# ESP32-S31 register map
Vendor: ESPRESSIF SYSTEMS (SHANGHAI) CO., LTD.; Series: ESP32 S-Series; File version: 1
CPU: RV32IMAFC r0p0, little endian, no MPU, FPU, 0 interrupt priority bits
Address unit: 32 bits
Registers are 32-bit, read-write, reset 0x0 unless marked. A register's access mark holds for its fields unless they carry their own. Offsets are from the block's base; [hi:lo] are bit positions; {n}, {i} and the like mark numbered series.

## MCPWM0 — Motor Control Pulse-Width Modulation 0
Base 0x20381000
Same registers: MCPWM1 0x20382000, MCPWM2 0x20383000, MCPWM3 0x20384000
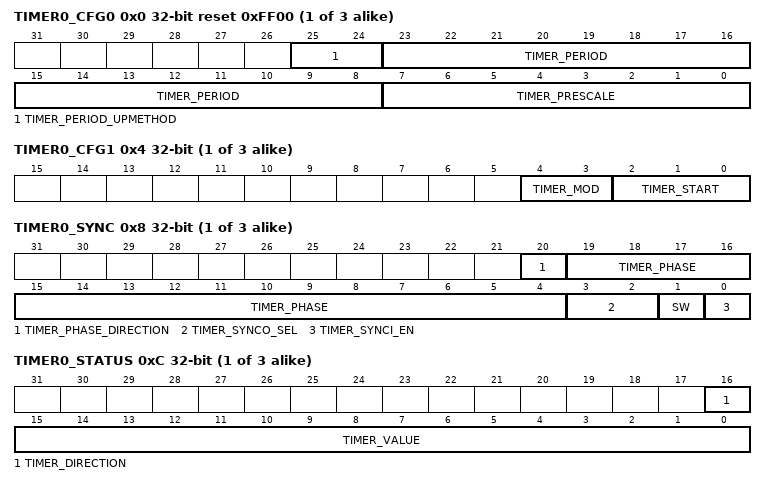
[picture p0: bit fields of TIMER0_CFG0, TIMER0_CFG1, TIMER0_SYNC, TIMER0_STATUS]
{0x0+0x10*i} TIMER{i}_CFG0 (i=0..2) reset 0xFF00 — PWM timer{i} period and update method configuration register.
  [25:24] TIMER_PERIOD_UPMETHOD — Configures the update method for active register of PWM timer%s period.\\0: Immediate\\1: TEZ\\2: Sync\\3: TEZ or sync\\TEZ here and below means timer equal zero event
  [23:8] TIMER_PERIOD — Configures the period shadow of PWM timer%s
  [7:0] TIMER_PRESCALE — Configures the prescaler value of timer%s, so that the period of PT0_clk = Period of PWM_clk * (PWM_TIMER%s_PRESCALE + 1)
{0x4+0x10*i} TIMER{i}_CFG1 (i=0..2) — PWM timer{i} working mode and start/stop control register.
  [4:3] TIMER_MOD — Configures the working mode of PWM timer%s.\\0: Freeze\\1: Increase mode\\2: Decrease mode\\3: Up-down mode
  [2:0] TIMER_START — Configures whether or not to start/stop PWM timer%s.\\0: If PWM timer%s starts, then stops at TEZ\\1: If timer%s starts, then stops at TEP\\2: PWM timer%s starts and runs on\\3: Timer%s starts and stops at the next TEZ\\4: Timer0 starts and stops at the next TEP.\\TEP here and below means the event that happens when the timer equals to period
{0x8+0x10*i} TIMER{i}_SYNC (i=0..2) — PWM timer{i} sync function configuration register.
  [20] TIMER_PHASE_DIRECTION — Configures the PWM timer%s's direction when timer%s mode is up-down mode.\\0: Increase\\1: Decrease
  [19:4] TIMER_PHASE — Configures the phase for timer%s reload on sync event.
  [3:2] TIMER_SYNCO_SEL — Configures the selection of PWM timer%s sync_out.\\0: Sync_in\\1: TEZ\\2: TEP\\3: Invalid, sync_out selects noting
  [1] SW — Configures the generation of software sync. Toggling this bit will trigger a software sync.
  [0] TIMER_SYNCI_EN — Configures whether or not to enable timer%s reloading with phase on sync input event is enabled.\\0: Disable\\1: Enable
{0xC+0x10*i} TIMER{i}_STATUS (i=0..2) ro — PWM timer{i} status register.
  [16] TIMER_DIRECTION — Represents current PWM timer%s counter direction.\\0: Increment\\1: Decrement
  [15:0] TIMER_VALUE — Represents current PWM timer%s counter value.
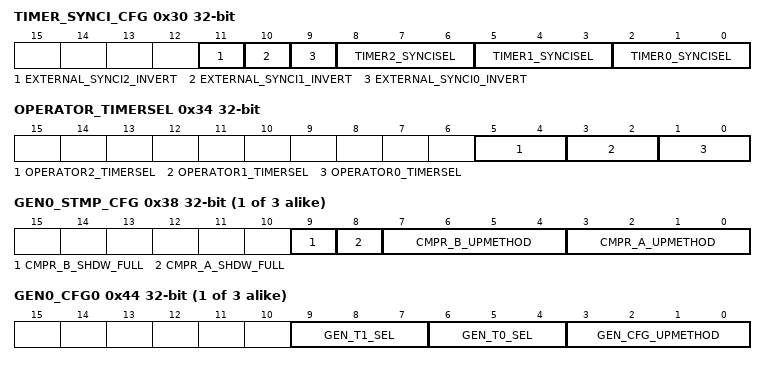
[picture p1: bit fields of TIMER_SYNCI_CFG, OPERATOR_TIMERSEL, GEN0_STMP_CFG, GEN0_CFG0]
0x30 TIMER_SYNCI_CFG — Synchronization input selection register for PWM timers.
  [11] EXTERNAL_SYNCI2_INVERT — Configures whether or not to invert SYNC2 from GPIO matrix.\\0: Not invert\\1: Invert
  [10] EXTERNAL_SYNCI1_INVERT — Configures whether or not to invert SYNC1 from GPIO matrix.\\0: Not invert\\1: Invert
  [9] EXTERNAL_SYNCI0_INVERT — Configures whether or not to invert SYNC0 from GPIO matrix.\\0: Not invert\\1: Invert
  [8:6] TIMER2_SYNCISEL — Configures the selection of sync input for PWM timer2.\\1: PWM timer0 sync_out\\2: PWM timer1 sync_out\\3: PWM timer2 sync_out\\4: SYNC0 from GPIO matrix\\5: SYNC1 from GPIO matrix\\6: SYNC2 from GPIO matrix\\Other values: No sync input selected
  [5:3] TIMER1_SYNCISEL — Configures the selection of sync input for PWM timer1.\\1: PWM timer0 sync_out\\2: PWM timer1 sync_out\\3: PWM timer2 sync_out\\4: SYNC0 from GPIO matrix\\5: SYNC1 from GPIO matrix\\6: SYNC2 from GPIO matrix\\Other values: No sync input selected
  [2:0] TIMER0_SYNCISEL — Configures the selection of sync input for PWM timer0.\\1: PWM timer0 sync_out\\2: PWM timer1 sync_out\\3: PWM timer2 sync_out\\4: SYNC0 from GPIO matrix\\5: SYNC1 from GPIO matrix\\6: SYNC2 from GPIO matrix\\Other values: No sync input selected
0x34 OPERATOR_TIMERSEL — PWM operator's timer select register
  [5:4] OPERATOR2_TIMERSEL — Configures which PWM timer will be the timing reference for PWM operator2.\\0: Timer0\\1: Timer1\\2: Timer2\\3: Invalid, will select timer2
  [3:2] OPERATOR1_TIMERSEL — Configures which PWM timer will be the timing reference for PWM operator1.\\0: Timer0\\1: Timer1\\2: Timer2\\3: Invalid, will select timer2
  [1:0] OPERATOR0_TIMERSEL — Configures which PWM timer will be the timing reference for PWM operator0.\\0: Timer0\\1: Timer1\\2: Timer2\\3: Invalid, will select timer2
{0x38+0x38*i} GEN{i}_STMP_CFG (i=0..2) — Generator{i} time stamp registers A and B transfer status and update method register
  [9] CMPR_B_SHDW_FULL — Represents whether or not generator%s time stamp B's shadow reg is transferred.\\0: B's active reg has been updated with shadow register latest value.\\1: B's shadow reg is filled and waiting to be transferred to B's active reg
  [8] CMPR_A_SHDW_FULL — Represents whether or not generator%s time stamp A's shadow reg is transferred.\\0: A's active reg has been updated with shadow register latest value.\\1: A's shadow reg is filled and waiting to be transferred to A's active reg
  [7:4] CMPR_B_UPMETHOD — Configures the update method for PWM generator %s time stamp B's active register.\\0: Immediately\\Bit0 is set to 1: TEZ\\Bit1 is set to 1: TEP\\Bit2 is set to 1: Sync\\Bit3 is set to 1: Disable the update
  [3:0] CMPR_A_UPMETHOD — Configures the update method for PWM generator %s time stamp A's active register.\\0: Immediately\\Bit0 is set to 1: TEZ\\Bit1 is set to 1: TEP\\Bit2 is set to 1: Sync\\Bit3 is set to 1: Disable the update
{0x3C+0x38*i} GEN{i}_TSTMP_A (i=0..2) — Generator{i} time stamp A's shadow register
  [15:0] CMPR_A — Configures the value of PWM generator %s time stamp A's shadow register.
{0x40+0x38*i} GEN{i}_TSTMP_B (i=0..2) — Generator{i} time stamp B's shadow register
  [15:0] CMPR_B — Configures the value of PWM generator %s time stamp B's shadow register.
{0x44+0x38*i} GEN{i}_CFG0 (i=0..2) — Generator{i} fault event T0 and T1 configuration register
  [9:7] GEN_T1_SEL — Configures source selection for PWM generator %s event_t1, take effect immediately.\\0: fault_event0\\1: fault_event1\\2: fault_event2\\3: sync_taken\\4: Invalid, Select nothing
  [6:4] GEN_T0_SEL — Configures source selection for PWM generator %s event_t0, take effect immediately.\\0: fault_event0\\1: fault_event1\\2: fault_event2\\3: sync_taken\\4: Invalid, Select nothing
  [3:0] GEN_CFG_UPMETHOD — Configures update method for PWM generator %s's active register.\\0: Immediately\\Bit0 is set to 1: TEZ\\Bit1 is set to 1: TEP\\Bit2 is set to 1: Sync\\Bit3 is set to 1: Disable the update
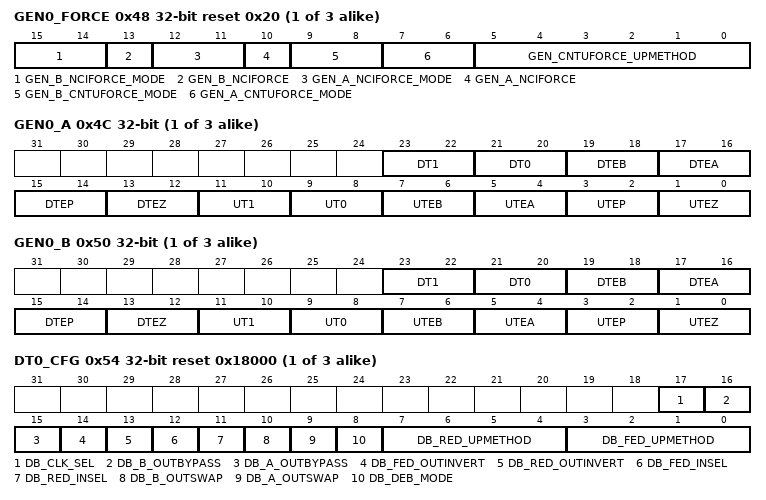
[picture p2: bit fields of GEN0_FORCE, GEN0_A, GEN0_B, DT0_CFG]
{0x48+0x38*i} GEN{i}_FORCE (i=0..2) reset 0x20 — Generator{i} output signal force mode register.
  [15:14] GEN_B_NCIFORCE_MODE — Configures non-continuous immediate software force mode for PWM%s B.\\0: Disabled\\1: Low\\2: High\\3: Disabled
  [13] GEN_B_NCIFORCE — Configures the generation of non-continuous immediate software-force event for PWM%s B, a toggle will trigger a force event.
  [12:11] GEN_A_NCIFORCE_MODE — Configures non-continuous immediate software force mode for PWM%s A.\\0: Disabled\\1: Low\\2: High\\3: Disabled
  [10] GEN_A_NCIFORCE — Configures the generation of non-continuous immediate software-force event for PWM%s A, a toggle will trigger a force event.
  [9:8] GEN_B_CNTUFORCE_MODE — Configures continuous software force mode for PWM%s B.\\0: Disabled\\1: Low\\2: High\\3: Disabled
  [7:6] GEN_A_CNTUFORCE_MODE — Configures continuous software force mode for PWM%s A.\\0: Disabled\\1: Low\\2: High\\3: Disabled
  [5:0] GEN_CNTUFORCE_UPMETHOD — Configures update method for continuous software force of PWM generator%s.\\0: Immediately\\Bit0 is set to 1: TEZ\\Bit1 is set to 1: TEP\\Bit2 is set to 1: TEA\\Bit3 is set to 1: TEB\\Bit4 is set to 1: Sync\\Bit5 is set to 1: Disable update. TEA/B here and below means an event generated when the timer's value equals to that of register A/B.
{0x4C+0x38*i} GEN{i}_A (i=0..2) — PWM{i} output signal A actions configuration register
  [23:22] DT1 — Configures action on PWM%s A triggered by event_t1 when timer decreasing.\\0: No change\\1: Low\\2: High\\3: Toggle
  [21:20] DT0 — Configures action on PWM%s A triggered by event_t0 when timer decreasing.\\0: No change\\1: Low\\2: High\\3: Toggle
  [19:18] DTEB — Configures action on PWM%s A triggered by event TEB when timer decreasing.\\0: No change\\1: Low\\2: High\\3: Toggle
  [17:16] DTEA — Configures action on PWM%s A triggered by event TEA when timer decreasing.\\0: No change\\1: Low\\2: High\\3: Toggle
  [15:14] DTEP — Configures action on PWM%s A triggered by event TEP when timer decreasing.\\0: No change\\1: Low\\2: High\\3: Toggle
  [13:12] DTEZ — Configures action on PWM%s A triggered by event TEZ when timer decreasing.\\0: No change\\1: Low\\2: High\\3: Toggle
  [11:10] UT1 — Configures action on PWM%s A triggered by event_t1 when timer increasing.\\0: No change\\1: Low\\2: High\\3: Toggle
  [9:8] UT0 — Configures action on PWM%s A triggered by event_t0 when timer increasing.\\0: No change\\1: Low\\2: High\\3: Toggle
  [7:6] UTEB — Configures action on PWM%s A triggered by event TEB when timer increasing.\\0: No change\\1: Low\\2: High\\3: Toggle
  [5:4] UTEA — Configures action on PWM%s A triggered by event TEA when timer increasing.\\0: No change\\1: Low\\2: High\\3: Toggle
  [3:2] UTEP — Configures action on PWM%s A triggered by event TEP when timer increasing.\\0: No change\\1: Low\\2: High\\3: Toggle
  [1:0] UTEZ — Configures action on PWM%s A triggered by event TEZ when timer increasing.\\0: No change\\1: Low\\2: High\\3: Toggle
{0x50+0x38*i} GEN{i}_B (i=0..2) — PWM{i} output signal B actions configuration register
  [23:22] DT1 — Configures action on PWM%s B triggered by event_t1 when timer decreasing.\\0: No change\\1: Low\\2: High\\3: Toggle
  [21:20] DT0 — Configures action on PWM%s B triggered by event_t0 when timer decreasing.\\0: No change\\1: Low\\2: High\\3: Toggle
  [19:18] DTEB — Configures action on PWM%s B triggered by event TEB when timer decreasing.\\0: No change\\1: Low\\2: High\\3: Toggle
  [17:16] DTEA — Configures action on PWM%s B triggered by event TEA when timer decreasing.\\0: No change\\1: Low\\2: High\\3: Toggle
  [15:14] DTEP — Configures action on PWM%s B triggered by event TEP when timer decreasing.\\0: No change\\1: Low\\2: High\\3: Toggle
  [13:12] DTEZ — Configures action on PWM%s B triggered by event TEZ when timer decreasing.\\0: No change\\1: Low\\2: High\\3: Toggle
  [11:10] UT1 — Configures action on PWM%s B triggered by event_t1 when timer increasing.\\0: No change\\1: Low\\2: High\\3: Toggle
  [9:8] UT0 — Configures action on PWM%s B triggered by event_t0 when timer increasing.\\0: No change\\1: Low\\2: High\\3: Toggle
  [7:6] UTEB — Configures action on PWM%s B triggered by event TEB when timer increasing.\\0: No change\\1: Low\\2: High\\3: Toggle
  [5:4] UTEA — Configures action on PWM%s B triggered by event TEA when timer increasing.\\0: No change\\1: Low\\2: High\\3: Toggle
  [3:2] UTEP — Configures action on PWM%s B triggered by event TEP when timer increasing.\\0: No change\\1: Low\\2: High\\3: Toggle
  [1:0] UTEZ — Configures action on PWM%s B triggered by event TEZ when timer increasing.\\0: No change\\1: Low\\2: High\\3: Toggle
{0x54+0x38*i} DT{i}_CFG (i=0..2) reset 0x18000 — Dead time configuration register
  [17] DB_CLK_SEL — Configures dead time generator %s clock selection.\\0: PWM_clk\\1: PT_clk
  [16] DB_B_OUTBYPASS — Configures S0 in table.
  [15] DB_A_OUTBYPASS — Configures S1 in table.
  [14] DB_FED_OUTINVERT — Configures S3 in table.
  [13] DB_RED_OUTINVERT — Configures S2 in table.
  [12] DB_FED_INSEL — Configures S5 in table.
  [11] DB_RED_INSEL — Configures S4 in table.
  [10] DB_B_OUTSWAP — Configures S7 in table.
  [9] DB_A_OUTSWAP — Configures S6 in table.
  [8] DB_DEB_MODE — Configures S8 in table, dual-edge B mode.\\0: fed/red take effect on different path separately\\1: fed/red take effect on B path, A out is in bypass or dulpB mode
  [7:4] DB_RED_UPMETHOD — Configures update method for RED (rising edge delay) active register.\\0: Immediate\\Bit0 is set to 1: TEZ\\Bit1 is set to 1: TEP\\Bit2 is set to 1: Sync\\Bit3 is set to 1: Disable the update
  [3:0] DB_FED_UPMETHOD — Configures update method for FED (Falling edge delay) active register.\\0: Immediate\\Bit0 is set to 1: TEZ\\Bit1 is set to 1: TEP\\Bit2 is set to 1: Sync\\Bit3 is set to 1: Disable the update
{0x58+0x38*i} DT{i}_FED_CFG (i=0..2) — Falling edge delay (FED) shadow register
  [15:0] DB_FED — Configures shadow register for FED.
{0x5C+0x38*i} DT{i}_RED_CFG (i=0..2) — Rising edge delay (RED) shadow register
  [15:0] DB_RED — Configures shadow register for RED.
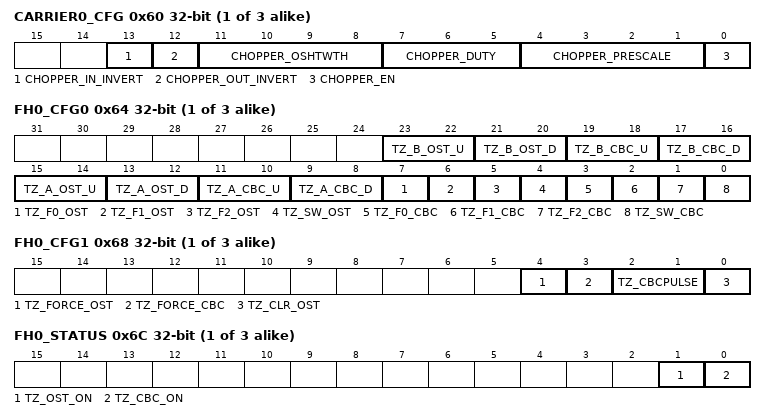
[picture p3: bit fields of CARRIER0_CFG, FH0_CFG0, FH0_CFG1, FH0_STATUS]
{0x60+0x38*i} CARRIER{i}_CFG (i=0..2) — Carrier{i} configuration register
  [13] CHOPPER_IN_INVERT — Configures whether or not to invert the input of PWM%s A and PWM%s B for this submodule.\\0: Normal\\1: Invert
  [12] CHOPPER_OUT_INVERT — Configures whether or not to invert the output of PWM%s A and PWM%s B for this submodule.\\0: Normal\\1: Invert
  [11:8] CHOPPER_OSHTWTH — Configures width of the first pulse. Measurement unit: Periods of the carrier.
  [7:5] CHOPPER_DUTY — Configures carrier duty. Duty = PWM_CARRIER%s_DUTY / 8
  [4:1] CHOPPER_PRESCALE — Configures the prescale value of PWM carrier%s clock (PC_clk), so that period of PC_clk = period of PWM_clk * (PWM_CARRIER%s_PRESCALE + 1)
  [0] CHOPPER_EN — Configures whether or not to enable carrier%s.\\0: Bypassed\\1: Enabled
{0x64+0x38*i} FH{i}_CFG0 (i=0..2) — PWM{i} A and PWM{i} B trip events actions configuration register
  [23:22] TZ_B_OST_U — Configures one-shot mode action on PWM%s B when fault event occurs and timer is increasing.\\0: Do nothing\\1: Force low\\2: Force high\\3: Toggle
  [21:20] TZ_B_OST_D — Configures one-shot mode action on PWM%s B when fault event occurs and timer is decreasing.\\0: Do nothing\\1: Force low\\2: Force high\\3: Toggle
  [19:18] TZ_B_CBC_U — Configures cycle-by-cycle mode action on PWM%s B when fault event occurs and timer is increasing.\\0: Do nothing\\1: Force low\\2: Force high\\3: Toggle
  [17:16] TZ_B_CBC_D — Configures cycle-by-cycle mode action on PWM%s B when fault event occurs and timer is decreasing.\\0: Do nothing\\1: Force low\\2: Force high\\3: Toggle
  [15:14] TZ_A_OST_U — Configures one-shot mode action on PWM%s A when fault event occurs and timer is increasing.\\0: Do nothing\\1: Force low\\2: Force high\\3: Toggle
  [13:12] TZ_A_OST_D — Configures one-shot mode action on PWM%s A when fault event occurs and timer is decreasing.\\0: Do nothing\\1: Force low\\2: Force high\\3: Toggle
  [11:10] TZ_A_CBC_U — Configures cycle-by-cycle mode action on PWM%s A when fault event occurs and timer is increasing.\\0: Do nothing\\1: Force low\\2: Force high\\3: Toggle
  [9:8] TZ_A_CBC_D — Configures cycle-by-cycle mode action on PWM%s A when fault event occurs and timer is decreasing.\\0: Do nothing\\1: Force low\\2: Force high\\3: Toggle
  [7] TZ_F0_OST — Configures whether or not event_f0 will trigger one-shot mode action.\\0: Disable\\1: Enable
  [6] TZ_F1_OST — Configures whether or not event_f1 will trigger one-shot mode action.\\0: Disable\\1: Enable
  [5] TZ_F2_OST — Configures whether or not event_f2 will trigger one-shot mode action.\\0: Disable\\1: Enable
  [4] TZ_SW_OST — Configures whether or not to enable software force one-shot mode action.\\0: Disable\\1: Enable
  [3] TZ_F0_CBC — Configures whether or not event_f0 will trigger cycle-by-cycle mode action.\\0: Disable\\1: Enable
  [2] TZ_F1_CBC — Configures whether or not event_f1 will trigger cycle-by-cycle mode action.\\0: Disable\\1: Enable
  [1] TZ_F2_CBC — Configures whether or not event_f2 will trigger cycle-by-cycle mode action.\\0: Disable\\1: Enable
  [0] TZ_SW_CBC — Configures whether or not to enable software force cycle-by-cycle mode action.\\0: Disable\\1: Enable
{0x68+0x38*i} FH{i}_CFG1 (i=0..2) — Software triggers for fault handler actions configuration register
  [4] TZ_FORCE_OST — Configures the generation of software one-shot mode action. A toggle (software negate its value) triggers a one-shot mode action.
  [3] TZ_FORCE_CBC — Configures the generation of software cycle-by-cycle mode action. A toggle (software negate its value) triggers a cycle-by-cycle mode action.
  [2:1] TZ_CBCPULSE — Configures the refresh moment selection of cycle-by-cycle mode action.\\0: Select nothing, will not refresh\\Bit0 is set to 1: TEZ\\Bit1 is set to 1: TEP
  [0] TZ_CLR_OST — Configures the generation of software one-shot mode action clear. A toggle (software negate its value) triggers a clear for on going one-shot mode action.
{0x6C+0x38*i} FH{i}_STATUS (i=0..2) ro — Fault events status register
  [1] TZ_OST_ON — Represents whether or not an one-shot mode action is on going.\\0:No action\\1: On going
  [0] TZ_CBC_ON — Represents whether or not an cycle-by-cycle mode action is on going.\\0:No action\\1: On going
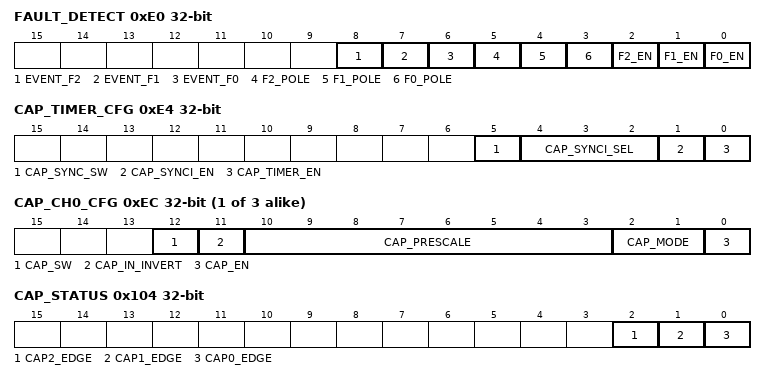
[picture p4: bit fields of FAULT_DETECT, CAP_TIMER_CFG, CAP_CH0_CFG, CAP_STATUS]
0xE0 FAULT_DETECT access per field — Fault detection configuration and status register
  [8] EVENT_F2 ro — Represents whether or not an event_f2 is on going.\\0: No action\\1: On going
  [7] EVENT_F1 ro — Represents whether or not an event_f1 is on going.\\0: No action\\1: On going
  [6] EVENT_F0 ro — Represents whether or not an event_f0 is on going.\\0: No action\\1: On going
  [5] F2_POLE rw — Configures event_f2 trigger polarity on FAULT2 source from GPIO matrix.\\0: Level low\\1: Level high
  [4] F1_POLE rw — Configures event_f1 trigger polarity on FAULT1 source from GPIO matrix.\\0: Level low\\1: Level high
  [3] F0_POLE rw — Configures event_f0 trigger polarity on FAULT0 source from GPIO matrix.\\0: Level low\\1: Level high
  [2] F2_EN rw — Configures whether or not to enable event_f2 generation.\\0: Disable\\1: Enable
  [1] F1_EN rw — Configures whether or not to enable event_f1 generation.\\0: Disable\\1: Enable
  [0] F0_EN rw — Configures whether or not to enable event_f0 generation.\\0: Disable\\1: Enable
0xE4 CAP_TIMER_CFG access per field — Capture timer configuration register
  [5] CAP_SYNC_SW wo — Configures the generation of a capture timer sync when reg_cap_synci_en is 1.\\0: Invalid, No effect\\1: Trigger a capture timer sync, capture timer is loaded with value in phase register
  [4:2] CAP_SYNCI_SEL rw — Configures the selection of capture module sync input.\\0: None\\1: Timer0 sync_out\\2: Timer1 sync_out\\3: Timer2 sync_out\\4: SYNC0 from GPIO matrix\\5: SYNC1 from GPIO matrix\\6: SYNC2 from GPIO matrix\\7: None
  [1] CAP_SYNCI_EN rw — Configures whether or not to enable capture timer sync.\\0: Disable\\1: Enable
  [0] CAP_TIMER_EN rw — Configures whether or not to enable capture timer increment.\\0: Disable\\1: Enable
0xE8 CAP_TIMER_PHASE — Capture timer sync phase register
  [31:0] CAP_PHASE — Configures phase value for capture timer sync operation.
{0xEC+4i} CAP_CH{i}_CFG (i=0..2) access per field — Capture channel {i} configuration register
  [12] CAP_SW wo — Configures the generation of software capture.\\0: Invalid, No effect\\1: Trigger a software forced capture on channel %s
  [11] CAP_IN_INVERT rw — Configures whether or not to invert CAP%s from GPIO matrix before prescale.\\0: Normal\\1: Invert
  [10:3] CAP_PRESCALE rw — Configures prescale value on possitive edge of CAP%s. Prescale value = PWM_CAP%s_PRESCALE + 1
  [2:1] CAP_MODE rw — Configures which edge of capture on channel %s after prescaling is used.\\0: None\\Bit0 is set to 1: Rnable capture on the negative edge\\Bit1 is set to 1: Enable capture on the positive edge
  [0] CAP_EN rw — Configures whether or not to enable capture on channel %s.\\0: Disable\\1: Enable
{0xF8+4i} CAP_CH{i} (i=0..2) ro — CAP{i} capture value register
  [31:0] CAP_VALUE — Represents value of last capture on CAP%s
0x104 CAP_STATUS ro — Last capture trigger edge information register
  [2] CAP2_EDGE — Represents edge of last capture trigger on channel2.\\0: Posedge\\1: Negedge
  [1] CAP1_EDGE — Represents edge of last capture trigger on channel1.\\0: Posedge\\1: Negedge
  [0] CAP0_EDGE — Represents edge of last capture trigger on channel0.\\0: Posedge\\1: Negedge
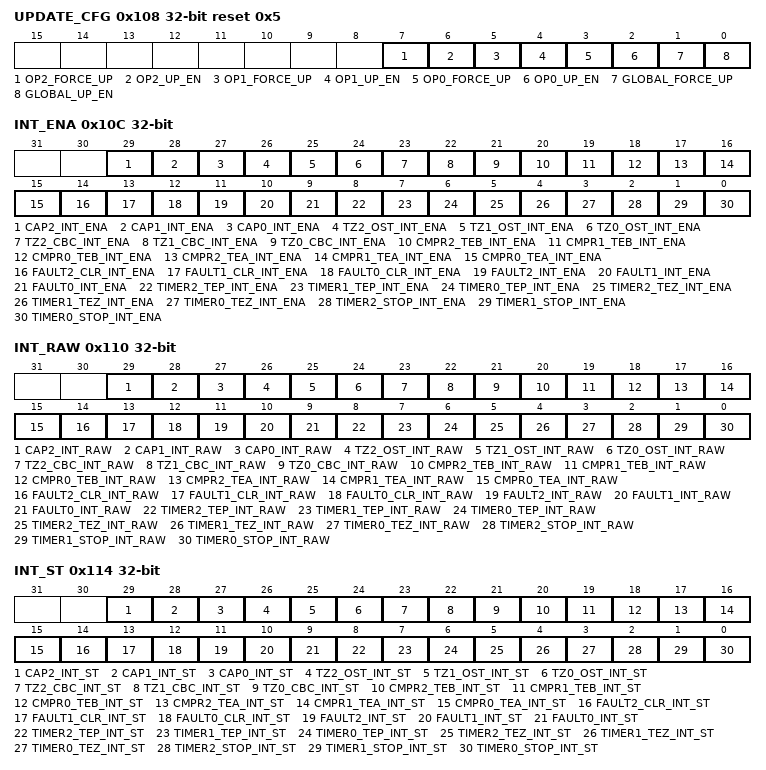
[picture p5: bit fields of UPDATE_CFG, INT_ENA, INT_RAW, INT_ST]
0x108 UPDATE_CFG reset 0x5 — Generator Update configuration register
  [7] OP2_FORCE_UP — Configures the generation of forced update for active registers in PWM operator2. A toggle (software invert its value) will trigger a forced update. Valid only when MCPWM_GLOBAL_UP_EN and MCPWM_OP2_UP_EN are both set to 1.
  [6] OP2_UP_EN — Configures whether or not to enable update of active registers in PWM operator2. Valid only when PWM_GLOBAL_UP_EN is set to 1.\\0: Disable\\1: Enable
  [5] OP1_FORCE_UP — Configures the generation of forced update for active registers in PWM operator1. A toggle (software invert its value) will trigger a forced update. Valid only when MCPWM_GLOBAL_UP_EN and MCPWM_OP1_UP_EN are both set to 1.
  [4] OP1_UP_EN — Configures whether or not to enable update of active registers in PWM operator1. Valid only when PWM_GLOBAL_UP_EN is set to 1.\\0: Disable\\1: Enable
  [3] OP0_FORCE_UP — Configures the generation of forced update for active registers in PWM operator0. A toggle (software invert its value) will trigger a forced update. Valid only when MCPWM_GLOBAL_UP_EN and MCPWM_OP0_UP_EN are both set to 1.
  [2] OP0_UP_EN — Configures whether or not to enable update of active registers in PWM operator0. Valid only when PWM_GLOBAL_UP_EN is set to 1.\\0: Disable\\1: Enable
  [1] GLOBAL_FORCE_UP — Configures the generation of global forced update for all active registers in MCPWM module. A toggle (software invert its value) will trigger a global forced update. Valid only when MCPWM_GLOBAL_UP_EN and MCPWM_OP0/1/2_UP_EN are both set to 1.
  [0] GLOBAL_UP_EN — Configures whether or not to enable global update for all active registers in MCPWM module.\\0: Disable\\1: Enable
0x10C INT_ENA — Interrupt enable register
  [29] CAP2_INT_ENA — Enable bit: Write 1 to enable the interrupt triggered by capture on CAP2.
  [28] CAP1_INT_ENA — Enable bit: Write 1 to enable the interrupt triggered by capture on CAP1.
  [27] CAP0_INT_ENA — Enable bit: Write 1 to enable the interrupt triggered by capture on CAP0.
  [26] TZ2_OST_INT_ENA — Enable bit: Write 1 to enable the interrupt triggered by a one-shot mode action on PWM2.
  [25] TZ1_OST_INT_ENA — Enable bit: Write 1 to enable the interrupt triggered by a one-shot mode action on PWM1.
  [24] TZ0_OST_INT_ENA — Enable bit: Write 1 to enable the interrupt triggered by a one-shot mode action on PWM0.
  [23] TZ2_CBC_INT_ENA — Enable bit: Write 1 to enable the interrupt triggered by a cycle-by-cycle mode action on PWM2.
  [22] TZ1_CBC_INT_ENA — Enable bit: Write 1 to enable the interrupt triggered by a cycle-by-cycle mode action on PWM1.
  [21] TZ0_CBC_INT_ENA — Enable bit: Write 1 to enable the interrupt triggered by a cycle-by-cycle mode action on PWM0.
  [20] CMPR2_TEB_INT_ENA — Enable bit: Write 1 to enable the interrupt triggered by a PWM operator 2 TEB event.
  [19] CMPR1_TEB_INT_ENA — Enable bit: Write 1 to enable the interrupt triggered by a PWM operator 1 TEB event.
  [18] CMPR0_TEB_INT_ENA — Enable bit: Write 1 to enable the interrupt triggered by a PWM operator 0 TEB event.
  [17] CMPR2_TEA_INT_ENA — Enable bit: Write 1 to enable the interrupt triggered by a PWM operator 2 TEA event.
  [16] CMPR1_TEA_INT_ENA — Enable bit: Write 1 to enable the interrupt triggered by a PWM operator 1 TEA event.
  [15] CMPR0_TEA_INT_ENA — Enable bit: Write 1 to enable the interrupt triggered by a PWM operator 0 TEA event.
  [14] FAULT2_CLR_INT_ENA — Enable bit: Write 1 to enable the interrupt triggered when event_f2 clears.
  [13] FAULT1_CLR_INT_ENA — Enable bit: Write 1 to enable the interrupt triggered when event_f1 clears.
  [12] FAULT0_CLR_INT_ENA — Enable bit: Write 1 to enable the interrupt triggered when event_f0 clears.
  [11] FAULT2_INT_ENA — Enable bit: Write 1 to enable the interrupt triggered when event_f2 starts.
  [10] FAULT1_INT_ENA — Enable bit: Write 1 to enable the interrupt triggered when event_f1 starts.
  [9] FAULT0_INT_ENA — Enable bit: Write 1 to enable the interrupt triggered when event_f0 starts.
  [8] TIMER2_TEP_INT_ENA — Enable bit: Write 1 to enable the interrupt triggered by a PWM timer 2 TEP event.
  [7] TIMER1_TEP_INT_ENA — Enable bit: Write 1 to enable the interrupt triggered by a PWM timer 1 TEP event.
  [6] TIMER0_TEP_INT_ENA — Enable bit: Write 1 to enable the interrupt triggered by a PWM timer 0 TEP event.
  [5] TIMER2_TEZ_INT_ENA — Enable bit: Write 1 to enable the interrupt triggered by a PWM timer 2 TEZ event.
  [4] TIMER1_TEZ_INT_ENA — Enable bit: Write 1 to enable the interrupt triggered by a PWM timer 1 TEZ event.
  [3] TIMER0_TEZ_INT_ENA — Enable bit: Write 1 to enable the interrupt triggered by a PWM timer 0 TEZ event.
  [2] TIMER2_STOP_INT_ENA — Enable bit: Write 1 to enable the interrupt triggered when the timer 2 stops.
  [1] TIMER1_STOP_INT_ENA — Enable bit: Write 1 to enable the interrupt triggered when the timer 1 stops.
  [0] TIMER0_STOP_INT_ENA — Enable bit: Write 1 to enable the interrupt triggered when the timer 0 stops.
0x110 INT_RAW — Interrupt raw status register
  [29] CAP2_INT_RAW — Raw status bit: The raw interrupt status of the interrupt triggered by capture on CAP2.
  [28] CAP1_INT_RAW — Raw status bit: The raw interrupt status of the interrupt triggered by capture on CAP1.
  [27] CAP0_INT_RAW — Raw status bit: The raw interrupt status of the interrupt triggered by capture on CAP0.
  [26] TZ2_OST_INT_RAW — Raw status bit: The raw interrupt status of the interrupt triggered by a one-shot mode action on PWM2.
  [25] TZ1_OST_INT_RAW — Raw status bit: The raw interrupt status of the interrupt triggered by a one-shot mode action on PWM1.
  [24] TZ0_OST_INT_RAW — Raw status bit: The raw interrupt status of the interrupt triggered by a one-shot mode action on PWM0.
  [23] TZ2_CBC_INT_RAW — Raw status bit: The raw interrupt status of the interrupt triggered by a cycle-by-cycle mode action on PWM2.
  [22] TZ1_CBC_INT_RAW — Raw status bit: The raw interrupt status of the interrupt triggered by a cycle-by-cycle mode action on PWM1.
  [21] TZ0_CBC_INT_RAW — Raw status bit: The raw interrupt status of the interrupt triggered by a cycle-by-cycle mode action on PWM0.
  [20] CMPR2_TEB_INT_RAW — Raw status bit: The raw interrupt status of the interrupt triggered by a PWM operator 2 TEB event
  [19] CMPR1_TEB_INT_RAW — Raw status bit: The raw interrupt status of the interrupt triggered by a PWM operator 1 TEB event
  [18] CMPR0_TEB_INT_RAW — Raw status bit: The raw interrupt status of the interrupt triggered by a PWM operator 0 TEB event
  [17] CMPR2_TEA_INT_RAW — Raw status bit: The raw interrupt status of the interrupt triggered by a PWM operator 2 TEA event
  [16] CMPR1_TEA_INT_RAW — Raw status bit: The raw interrupt status of the interrupt triggered by a PWM operator 1 TEA event
  [15] CMPR0_TEA_INT_RAW — Raw status bit: The raw interrupt status of the interrupt triggered by a PWM operator 0 TEA event
  [14] FAULT2_CLR_INT_RAW — Raw status bit: The raw interrupt status of the interrupt triggered when event_f2 clears.
  [13] FAULT1_CLR_INT_RAW — Raw status bit: The raw interrupt status of the interrupt triggered when event_f1 clears.
  [12] FAULT0_CLR_INT_RAW — Raw status bit: The raw interrupt status of the interrupt triggered when event_f0 clears.
  [11] FAULT2_INT_RAW — Raw status bit: The raw interrupt status of the interrupt triggered when event_f2 starts.
  [10] FAULT1_INT_RAW — Raw status bit: The raw interrupt status of the interrupt triggered when event_f1 starts.
  [9] FAULT0_INT_RAW — Raw status bit: The raw interrupt status of the interrupt triggered when event_f0 starts.
  [8] TIMER2_TEP_INT_RAW — Raw status bit: The raw interrupt status of the interrupt triggered by a PWM timer 2 TEP event.
  [7] TIMER1_TEP_INT_RAW — Raw status bit: The raw interrupt status of the interrupt triggered by a PWM timer 1 TEP event.
  [6] TIMER0_TEP_INT_RAW — Raw status bit: The raw interrupt status of the interrupt triggered by a PWM timer 0 TEP event.
  [5] TIMER2_TEZ_INT_RAW — Raw status bit: The raw interrupt status of the interrupt triggered by a PWM timer 2 TEZ event.
  [4] TIMER1_TEZ_INT_RAW — Raw status bit: The raw interrupt status of the interrupt triggered by a PWM timer 1 TEZ event.
  [3] TIMER0_TEZ_INT_RAW — Raw status bit: The raw interrupt status of the interrupt triggered by a PWM timer 0 TEZ event.
  [2] TIMER2_STOP_INT_RAW — Raw status bit: The raw interrupt status of the interrupt triggered when the timer 2 stops.
  [1] TIMER1_STOP_INT_RAW — Raw status bit: The raw interrupt status of the interrupt triggered when the timer 1 stops.
  [0] TIMER0_STOP_INT_RAW — Raw status bit: The raw interrupt status of the interrupt triggered when the timer 0 stops.
0x114 INT_ST ro — Interrupt masked status register
  [29] CAP2_INT_ST — Masked status bit: The masked interrupt status of the interrupt triggered by capture on CAP2.
  [28] CAP1_INT_ST — Masked status bit: The masked interrupt status of the interrupt triggered by capture on CAP1.
  [27] CAP0_INT_ST — Masked status bit: The masked interrupt status of the interrupt triggered by capture on CAP0.
  [26] TZ2_OST_INT_ST — Masked status bit: The masked interrupt status of the interrupt triggered by a one-shot mode action on PWM2.
  [25] TZ1_OST_INT_ST — Masked status bit: The masked interrupt status of the interrupt triggered by a one-shot mode action on PWM1.
  [24] TZ0_OST_INT_ST — Masked status bit: The masked interrupt status of the interrupt triggered by a one-shot mode action on PWM0.
  [23] TZ2_CBC_INT_ST — Masked status bit: The masked interrupt status of the interrupt triggered by a cycle-by-cycle mode action on PWM2.
  [22] TZ1_CBC_INT_ST — Masked status bit: The masked interrupt status of the interrupt triggered by a cycle-by-cycle mode action on PWM1.
  [21] TZ0_CBC_INT_ST — Masked status bit: The masked interrupt status of the interrupt triggered by a cycle-by-cycle mode action on PWM0.
  [20] CMPR2_TEB_INT_ST — Masked status bit: The masked interrupt status of the interrupt triggered by a PWM operator 2 TEB event
  [19] CMPR1_TEB_INT_ST — Masked status bit: The masked interrupt status of the interrupt triggered by a PWM operator 1 TEB event
  [18] CMPR0_TEB_INT_ST — Masked status bit: The masked interrupt status of the interrupt triggered by a PWM operator 0 TEB event
  [17] CMPR2_TEA_INT_ST — Masked status bit: The masked interrupt status of the interrupt triggered by a PWM operator 2 TEA event
  [16] CMPR1_TEA_INT_ST — Masked status bit: The masked interrupt status of the interrupt triggered by a PWM operator 1 TEA event
  [15] CMPR0_TEA_INT_ST — Masked status bit: The masked interrupt status of the interrupt triggered by a PWM operator 0 TEA event
  [14] FAULT2_CLR_INT_ST — Masked status bit: The masked interrupt status of the interrupt triggered when event_f2 clears.
  [13] FAULT1_CLR_INT_ST — Masked status bit: The masked interrupt status of the interrupt triggered when event_f1 clears.
  [12] FAULT0_CLR_INT_ST — Masked status bit: The masked interrupt status of the interrupt triggered when event_f0 clears.
  [11] FAULT2_INT_ST — Masked status bit: The masked interrupt status of the interrupt triggered when event_f2 starts.
  [10] FAULT1_INT_ST — Masked status bit: The masked interrupt status of the interrupt triggered when event_f1 starts.
  [9] FAULT0_INT_ST — Masked status bit: The masked interrupt status of the interrupt triggered when event_f0 starts.
  [8] TIMER2_TEP_INT_ST — Masked status bit: The masked interrupt status of the interrupt triggered by a PWM timer 2 TEP event.
  [7] TIMER1_TEP_INT_ST — Masked status bit: The masked interrupt status of the interrupt triggered by a PWM timer 1 TEP event.
  [6] TIMER0_TEP_INT_ST — Masked status bit: The masked interrupt status of the interrupt triggered by a PWM timer 0 TEP event.
  [5] TIMER2_TEZ_INT_ST — Masked status bit: The masked interrupt status of the interrupt triggered by a PWM timer 2 TEZ event.
  [4] TIMER1_TEZ_INT_ST — Masked status bit: The masked interrupt status of the interrupt triggered by a PWM timer 1 TEZ event.
  [3] TIMER0_TEZ_INT_ST — Masked status bit: The masked interrupt status of the interrupt triggered by a PWM timer 0 TEZ event.
  [2] TIMER2_STOP_INT_ST — Masked status bit: The masked interrupt status of the interrupt triggered when the timer 2 stops.
  [1] TIMER1_STOP_INT_ST — Masked status bit: The masked interrupt status of the interrupt triggered when the timer 1 stops.
  [0] TIMER0_STOP_INT_ST — Masked status bit: The masked interrupt status of the interrupt triggered when the timer 0 stops.
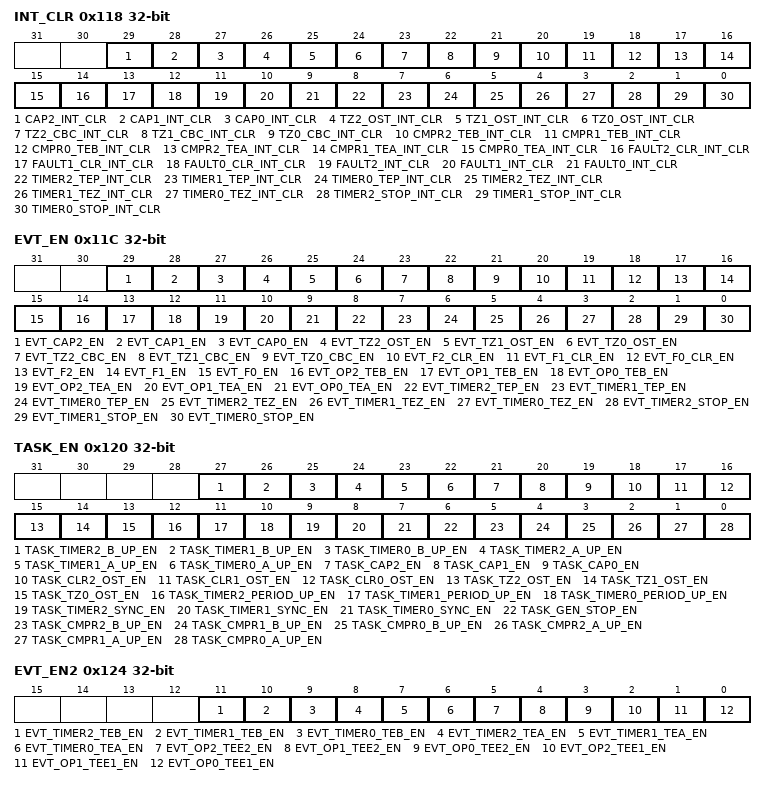
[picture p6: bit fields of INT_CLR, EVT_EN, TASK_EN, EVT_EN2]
0x118 INT_CLR wo — Interrupt clear register
  [29] CAP2_INT_CLR — Clear bit: Write 1 to clear the interrupt triggered by capture on CAP2.
  [28] CAP1_INT_CLR — Clear bit: Write 1 to clear the interrupt triggered by capture on CAP1.
  [27] CAP0_INT_CLR — Clear bit: Write 1 to clear the interrupt triggered by capture on CAP0.
  [26] TZ2_OST_INT_CLR — Clear bit: Write 1 to clear the interrupt triggered by a one-shot mode action on PWM2.
  [25] TZ1_OST_INT_CLR — Clear bit: Write 1 to clear the interrupt triggered by a one-shot mode action on PWM1.
  [24] TZ0_OST_INT_CLR — Clear bit: Write 1 to clear the interrupt triggered by a one-shot mode action on PWM0.
  [23] TZ2_CBC_INT_CLR — Clear bit: Write 1 to clear the interrupt triggered by a cycle-by-cycle mode action on PWM2.
  [22] TZ1_CBC_INT_CLR — Clear bit: Write 1 to clear the interrupt triggered by a cycle-by-cycle mode action on PWM1.
  [21] TZ0_CBC_INT_CLR — Clear bit: Write 1 to clear the interrupt triggered by a cycle-by-cycle mode action on PWM0.
  [20] CMPR2_TEB_INT_CLR — Clear bit: Write 1 to clear the interrupt triggered by a PWM operator 2 TEB event
  [19] CMPR1_TEB_INT_CLR — Clear bit: Write 1 to clear the interrupt triggered by a PWM operator 1 TEB event
  [18] CMPR0_TEB_INT_CLR — Clear bit: Write 1 to clear the interrupt triggered by a PWM operator 0 TEB event
  [17] CMPR2_TEA_INT_CLR — Clear bit: Write 1 to clear the interrupt triggered by a PWM operator 2 TEA event
  [16] CMPR1_TEA_INT_CLR — Clear bit: Write 1 to clear the interrupt triggered by a PWM operator 1 TEA event
  [15] CMPR0_TEA_INT_CLR — Clear bit: Write 1 to clear the interrupt triggered by a PWM operator 0 TEA event
  [14] FAULT2_CLR_INT_CLR — Clear bit: Write 1 to clear the interrupt triggered when event_f2 clears.
  [13] FAULT1_CLR_INT_CLR — Clear bit: Write 1 to clear the interrupt triggered when event_f1 clears.
  [12] FAULT0_CLR_INT_CLR — Clear bit: Write 1 to clear the interrupt triggered when event_f0 clears.
  [11] FAULT2_INT_CLR — Clear bit: Write 1 to clear the interrupt triggered when event_f2 starts.
  [10] FAULT1_INT_CLR — Clear bit: Write 1 to clear the interrupt triggered when event_f1 starts.
  [9] FAULT0_INT_CLR — Clear bit: Write 1 to clear the interrupt triggered when event_f0 starts.
  [8] TIMER2_TEP_INT_CLR — Clear bit: Write 1 to clear the interrupt triggered by a PWM timer 2 TEP event.
  [7] TIMER1_TEP_INT_CLR — Clear bit: Write 1 to clear the interrupt triggered by a PWM timer 1 TEP event.
  [6] TIMER0_TEP_INT_CLR — Clear bit: Write 1 to clear the interrupt triggered by a PWM timer 0 TEP event.
  [5] TIMER2_TEZ_INT_CLR — Clear bit: Write 1 to clear the interrupt triggered by a PWM timer 2 TEZ event.
  [4] TIMER1_TEZ_INT_CLR — Clear bit: Write 1 to clear the interrupt triggered by a PWM timer 1 TEZ event.
  [3] TIMER0_TEZ_INT_CLR — Clear bit: Write 1 to clear the interrupt triggered by a PWM timer 0 TEZ event.
  [2] TIMER2_STOP_INT_CLR — Clear bit: Write 1 to clear the interrupt triggered when the timer 2 stops.
  [1] TIMER1_STOP_INT_CLR — Clear bit: Write 1 to clear the interrupt triggered when the timer 1 stops.
  [0] TIMER0_STOP_INT_CLR — Clear bit: Write 1 to clear the interrupt triggered when the timer 0 stops.
0x11C EVT_EN — Event enable register
  [29] EVT_CAP2_EN — Configures whether or not to enable capture2 event generate.\\0: Disable\\1: Enable
  [28] EVT_CAP1_EN — Configures whether or not to enable capture1 event generate.\\0: Disable\\1: Enable
  [27] EVT_CAP0_EN — Configures whether or not to enable capture0 event generate.\\0: Disable\\1: Enable
  [26] EVT_TZ2_OST_EN — Configures whether or not to enable one-shot trip2 event generate.\\0: Disable\\1: Enable
  [25] EVT_TZ1_OST_EN — Configures whether or not to enable one-shot trip1 event generate.\\0: Disable\\1: Enable
  [24] EVT_TZ0_OST_EN — Configures whether or not to enable one-shot trip0 event generate.\\0: Disable\\1: Enable
  [23] EVT_TZ2_CBC_EN — Configures whether or not to enable cycle-by-cycle trip2 event generate.\\0: Disable\\1: Enable
  [22] EVT_TZ1_CBC_EN — Configures whether or not to enable cycle-by-cycle trip1 event generate.\\0: Disable\\1: Enable
  [21] EVT_TZ0_CBC_EN — Configures whether or not to enable cycle-by-cycle trip0 event generate.\\0: Disable\\1: Enable
  [20] EVT_F2_CLR_EN — Configures whether or not to enable fault2 clear event generate.\\0: Disable\\1: Enable
  [19] EVT_F1_CLR_EN — Configures whether or not to enable fault1 clear event generate.\\0: Disable\\1: Enable
  [18] EVT_F0_CLR_EN — Configures whether or not to enable fault0 clear event generate.\\0: Disable\\1: Enable
  [17] EVT_F2_EN — Configures whether or not to enable fault2 event generate.\\0: Disable\\1: Enable
  [16] EVT_F1_EN — Configures whether or not to enable fault1 event generate.\\0: Disable\\1: Enable
  [15] EVT_F0_EN — Configures whether or not to enable fault0 event generate.\\0: Disable\\1: Enable
  [14] EVT_OP2_TEB_EN — Configures whether or not to enable PWM generator2 timer equal b event generate.\\0: Disable\\1: Enable
  [13] EVT_OP1_TEB_EN — Configures whether or not to enable PWM generator1 timer equal b event generate.\\0: Disable\\1: Enable
  [12] EVT_OP0_TEB_EN — Configures whether or not to enable PWM generator0 timer equal b event generate.\\0: Disable\\1: Enable
  [11] EVT_OP2_TEA_EN — Configures whether or not to enable PWM generator2 timer equal a event generate.\\0: Disable\\1: Enable
  [10] EVT_OP1_TEA_EN — Configures whether or not to enable PWM generator1 timer equal a event generate.\\0: Disable\\1: Enable
  [9] EVT_OP0_TEA_EN — Configures whether or not to enable PWM generator0 timer equal a event generate.\\0: Disable\\1: Enable
  [8] EVT_TIMER2_TEP_EN — Configures whether or not to enable timer2 equal period event generate.\\0: Disable\\1: Enable
  [7] EVT_TIMER1_TEP_EN — Configures whether or not to enable timer1 equal period event generate.\\0: Disable\\1: Enable
  [6] EVT_TIMER0_TEP_EN — Configures whether or not to enable timer0 equal period event generate.\\0: Disable\\1: Enable
  [5] EVT_TIMER2_TEZ_EN — Configures whether or not to enable timer2 equal zero event generate.\\0: Disable\\1: Enable
  [4] EVT_TIMER1_TEZ_EN — Configures whether or not to enable timer1 equal zero event generate.\\0: Disable\\1: Enable
  [3] EVT_TIMER0_TEZ_EN — Configures whether or not to enable timer0 equal zero event generate.\\0: Disable\\1: Enable
  [2] EVT_TIMER2_STOP_EN — Configures whether or not to enable timer2 stop event generate.\\0: Disable\\1: Enable
  [1] EVT_TIMER1_STOP_EN — Configures whether or not to enable timer1 stop event generate.\\0: Disable\\1: Enable
  [0] EVT_TIMER0_STOP_EN — Configures whether or not to enable timer0 stop event generate.\\0: Disable\\1: Enable
0x120 TASK_EN — Task enable register
  [27] TASK_TIMER2_B_UP_EN — Configures whether or not to enable timer2 timestamp b update task receive.\\0: Disable\\1: Enable
  [26] TASK_TIMER1_B_UP_EN — Configures whether or not to enable timer1 timestamp b update task receive.\\0: Disable\\1: Enable
  [25] TASK_TIMER0_B_UP_EN — Configures whether or not to enable timer0 timestamp b update task receive.\\0: Disable\\1: Enable
  [24] TASK_TIMER2_A_UP_EN — Configures whether or not to enable timer2 timestamp a update task receive.\\0: Disable\\1: Enable
  [23] TASK_TIMER1_A_UP_EN — Configures whether or not to enable timer1 timestamp a update task receive.\\0: Disable\\1: Enable
  [22] TASK_TIMER0_A_UP_EN — Configures whether or not to enable timer0 timestamp a update task receive.\\0: Disable\\1: Enable
  [21] TASK_CAP2_EN — Configures whether or not to enable capture2 task receive.\\0: Disable\\1: Enable
  [20] TASK_CAP1_EN — Configures whether or not to enable capture1 task receive.\\0: Disable\\1: Enable
  [19] TASK_CAP0_EN — Configures whether or not to enable capture0 task receive.\\0: Disable\\1: Enable
  [18] TASK_CLR2_OST_EN — Configures whether or not to enable one shot trip2 clear task receive.\\0: Disable\\1: Enable
  [17] TASK_CLR1_OST_EN — Configures whether or not to enable one shot trip1 clear task receive.\\0: Disable\\1: Enable
  [16] TASK_CLR0_OST_EN — Configures whether or not to enable one shot trip0 clear task receive.\\0: Disable\\1: Enable
  [15] TASK_TZ2_OST_EN — Configures whether or not to enable one shot trip2 task receive.\\0: Disable\\1: Enable
  [14] TASK_TZ1_OST_EN — Configures whether or not to enable one shot trip1 task receive.\\0: Disable\\1: Enable
  [13] TASK_TZ0_OST_EN — Configures whether or not to enable one shot trip0 task receive.\\0: Disable\\1: Enable
  [12] TASK_TIMER2_PERIOD_UP_EN — Configures whether or not to enable timer2 period update task receive.\\0: Disable\\1: Enable
  [11] TASK_TIMER1_PERIOD_UP_EN — Configures whether or not to enable timer1 period update task receive.\\0: Disable\\1: Enable
  [10] TASK_TIMER0_PERIOD_UP_EN — Configures whether or not to enable timer0 period update task receive.\\0: Disable\\1: Enable
  [9] TASK_TIMER2_SYNC_EN — Configures whether or not to enable timer2 sync task receive.\\0: Disable\\1: Enable
  [8] TASK_TIMER1_SYNC_EN — Configures whether or not to enable timer1 sync task receive.\\0: Disable\\1: Enable
  [7] TASK_TIMER0_SYNC_EN — Configures whether or not to enable timer0 sync task receive.\\0: Disable\\1: Enable
  [6] TASK_GEN_STOP_EN — Configures whether or not to enable all PWM generate stop task receive.\\0: Disable\\1: Enable
  [5] TASK_CMPR2_B_UP_EN — Configures whether or not to enable PWM generator2 timer stamp B's shadow register update task receive.\\0: Disable\\1: Enable
  [4] TASK_CMPR1_B_UP_EN — Configures whether or not to enable PWM generator1 timer stamp B's shadow register update task receive.\\0: Disable\\1: Enable
  [3] TASK_CMPR0_B_UP_EN — Configures whether or not to enable PWM generator0 timer stamp B's shadow register update task receive.\\0: Disable\\1: Enable
  [2] TASK_CMPR2_A_UP_EN — Configures whether or not to enable PWM generator2 timer stamp A's shadow register update task receive.\\0: Disable\\1: Enable
  [1] TASK_CMPR1_A_UP_EN — Configures whether or not to enable PWM generator1 timer stamp A's shadow register update task receive.\\0: Disable\\1: Enable
  [0] TASK_CMPR0_A_UP_EN — Configures whether or not to enable PWM generator0 timer stamp A's shadow register update task receive.\\0: Disable\\1: Enable
0x124 EVT_EN2 — Event enable register2
  [11] EVT_TIMER2_TEB_EN — Configures whether or not to enable timer2 equal teb event generate.\\0: Disable\\1: Enable
  [10] EVT_TIMER1_TEB_EN — Configures whether or not to enable timer1 equal teb event generate.\\0: Disable\\1: Enable
  [9] EVT_TIMER0_TEB_EN — Configures whether or not to enable timer0 equal teb event generate.\\0: Disable\\1: Enable
  [8] EVT_TIMER2_TEA_EN — Configures whether or not to enable timer2 equal tea event generate.\\0: Disable\\1: Enable
  [7] EVT_TIMER1_TEA_EN — Configures whether or not to enable timer1 equal tea event generate.\\0: Disable\\1: Enable
  [6] EVT_TIMER0_TEA_EN — Configures whether or not to enable timer0 equal tea event generate.\\0: Disable\\1: Enable
  [5] EVT_OP2_TEE2_EN — Configures whether or not to enable PWM generator2 timer equal OP2_TSTMP_E2_REG event generate.\\0: Disable\\1: Enable
  [4] EVT_OP1_TEE2_EN — Configures whether or not to enable PWM generator1 timer equal OP1_TSTMP_E2_REG event generate.\\0: Disable\\1: Enable
  [3] EVT_OP0_TEE2_EN — Configures whether or not to enable PWM generator0 timer equal OP0_TSTMP_E2_REG event generate.\\0: Disable\\1: Enable
  [2] EVT_OP2_TEE1_EN — Configures whether or not to enable PWM generator2 timer equal OP2_TSTMP_E1_REG event generate.\\0: Disable\\1: Enable
  [1] EVT_OP1_TEE1_EN — Configures whether or not to enable PWM generator1 timer equal OP1_TSTMP_E1_REG event generate.\\0: Disable\\1: Enable
  [0] EVT_OP0_TEE1_EN — Configures whether or not to enable PWM generator0 timer equal OP0_TSTMP_E1_REG event generate.\\0: Disable\\1: Enable
{0x128+8i} OP{i}_TSTMP_E1 (i=0..2) — Generator{i} timer stamp E1 value register
  [15:0] OP_TSTMP_E1 — Configures generator%s timer stamp E1 value register
{0x12C+8i} OP{i}_TSTMP_E2 (i=0..2) — Generator{i} timer stamp E2 value register
  [15:0] OP_TSTMP_E2 — Configures generator%s timer stamp E2 value register
0x140 CLK — Global configuration register
  [0] EN — Configures whether or not to open register clock gate.\\0: Open the clock gate only when application writes registers\\1: Force open the clock gate for register
0x144 VERSION reset 0x2403190
  [27:0] DATE — Configures the version.
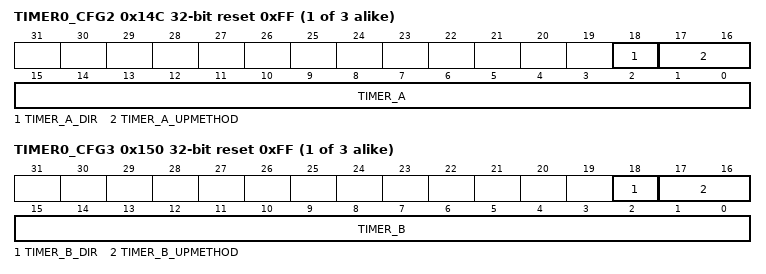
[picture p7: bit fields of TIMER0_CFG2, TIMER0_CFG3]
{0x14C+8i} TIMER{i}_CFG2 (i=0..2) reset 0xFF — PWM timer{i} timestamp a configuration register.
  [18] TIMER_A_DIR — Configures the direction of the timer when timer%s value equal a value for event trigger.\\0: up \\1: down
  [17:16] TIMER_A_UPMETHOD — Configures the update method for active register of PWM timer%s timestamp a.\\0: Immediate\\1: TEZ\\2: Sync\\3: TEZ or sync\\TEZ here and below means timer equal zero event
  [15:0] TIMER_A — Configures the timestamp a shadow of PWM timer%s
{0x150+8i} TIMER{i}_CFG3 (i=0..2) reset 0xFF — PWM timer{i} timestamp b configuration register.
  [18] TIMER_B_DIR — Configures the direction of the timer when timer%s value equal b value for event trigger.\\0: up \\1: down
  [17:16] TIMER_B_UPMETHOD — Configures the update method for active register of PWM timer%s timestamp b.\\0: Immediate\\1: TEZ\\2: Sync\\3: TEZ or sync\\TEZ here and below means timer equal zero event
  [15:0] TIMER_B — Configures the timestamp b shadow of PWM timer%s
